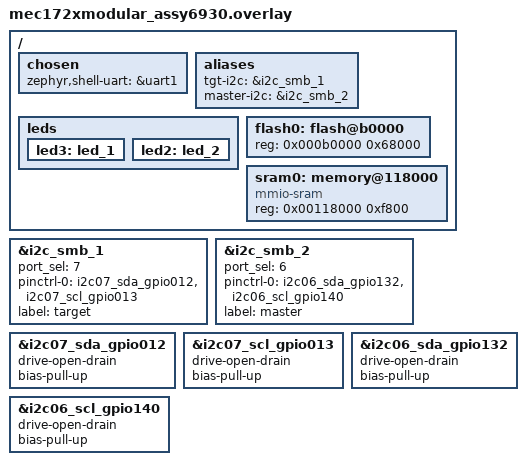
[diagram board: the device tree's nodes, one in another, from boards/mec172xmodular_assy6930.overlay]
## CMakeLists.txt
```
# SPDX-License-Identifier: Apache-2.0

cmake_minimum_required(VERSION 3.20.0)

find_package(Zephyr REQUIRED HINTS $ENV{ZEPHYR_BASE})
project(i2c_shell)

target_sources(app PRIVATE src/main.c)
target_sources(app PRIVATE src/i2c_target.c)
```

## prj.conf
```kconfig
# Driver
CONFIG_I2C=y
CONFIG_I2C_TARGET=y

# console
CONFIG_CONSOLE=y
CONFIG_UART_CONSOLE=y
CONFIG_LOG=y

#SHELL
CONFIG_SHELL=y
CONFIG_GPIO_SHELL=y
CONFIG_I2C_SHELL=y
CONFIG_SHELL_PROMPT_UART="MCHP:~$ "
```

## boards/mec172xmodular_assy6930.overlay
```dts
/*
 * Copyright (c) 2020 Intel Corporation
 *
 * SPDX-License-Identifier: Apache-2.0
 */


/ {
	chosen {
		zephyr,shell-uart = &uart1;
	};

	aliases {
        tgt-i2c = &i2c_smb_1;
        master-i2c = &i2c_smb_2;
    };

	leds {
		led3: led_1 {
			status = "okay";
		};
		led2: led_2 {
			status = "okay";
		};
	};

	/delete-node/ flash@c0000;
	/delete-node/ memory@118000;
	flash0: flash@b0000 {
		reg = <0x000b0000 0x68000>;
	};

	sram0: memory@118000 {
		compatible = "mmio-sram";
		reg = <0x00118000 0xf800>;
	};
};

// Target
&i2c_smb_1 {
    status = "okay";
    port_sel = <7>;
    pinctrl-0 = < &i2c07_sda_gpio012 &i2c07_scl_gpio013 >;  // TP257
	pinctrl-names = "default";

	// port_sel = <1>;
    // pinctrl-0 = < &i2c01_sda_gpio130 &i2c01_scl_gpio131 >;  // TP253
	// pinctrl-names = "default";

    label = "target";
};

// Master
&i2c_smb_2 {
    status = "okay";
    port_sel = <6>;
    pinctrl-0 = < &i2c06_sda_gpio132 &i2c06_scl_gpio140 >; // TP252
	pinctrl-names = "default";

    label = "master";
};

// &i2c01_sda_gpio130{
// 	drive-open-drain;
// 	bias-pull-up;
// };

// &i2c01_scl_gpio131{
// 	drive-open-drain;
// 	bias-pull-up;
// };

&i2c07_sda_gpio012{
	drive-open-drain;
	bias-pull-up;
};

&i2c07_scl_gpio013{
	drive-open-drain;
	bias-pull-up;
};

&i2c06_sda_gpio132{
	drive-open-drain;
	bias-pull-up;
};

&i2c06_scl_gpio140{
	drive-open-drain;
	bias-pull-up;
};
```

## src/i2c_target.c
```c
/*
 * @Author: andy.chang 
 * @Date: 2026-04-16 15:22:05 
 * @Last Modified by: andy.chang
 * @Last Modified time: 2026-04-23 14:50:15
 */

#include <zephyr/drivers/i2c.h>
#include <zephyr/kernel.h>
#include <zephyr/sys/printk.h>
#include <zephyr/logging/log.h>

LOG_MODULE_REGISTER(i2c_tgt, LOG_LEVEL_DBG);

static const struct device *bus = DEVICE_DT_GET(DT_ALIAS(tgt_i2c));

enum {
	I2C_STATE_IDLE = 0,
	I2C_STATE_START_WRITE,
	I2C_STATE_WRITE,
	I2C_STATE_READ,
};

static uint8_t i2c_state = I2C_STATE_IDLE;

static uint8_t idx = 0;
static uint8_t resp_buf[128] = {0};

/*
 * @brief Callback which is called when a write request is received from the
 * master.
 * @param config Pointer to the target configuration.
 */
static int acpi_target_write_requested_cb(struct i2c_target_config *config) {
    LOG_DBG("acpi target write requested");

    i2c_state = I2C_STATE_START_WRITE;
    idx = 0;

    return 0;
}

/*
 * @brief Callback which is called when a write is received from the master.
 * @param config Pointer to the target configuration.
 * @param val The byte received from the master.
 */
static int acpi_target_write_received_cb(struct i2c_target_config *config,
                                        uint8_t val) {
    LOG_DBG("acpi target write received: 0x%02x", val);

    resp_buf[idx++] = val;

    i2c_state = I2C_STATE_WRITE;
    return 0;
}

static int acpi_target_read_processed_cb(struct i2c_target_config *config, uint8_t *val);

static int acpi_target_read_requested_cb(struct i2c_target_config *config, uint8_t *val) {
    i2c_state = I2C_STATE_READ;
    idx = 0;

    return acpi_target_read_processed_cb(config, val);
}

/*
 * @brief Callback which is called when a read request is received from the
 * master.
 * @param config Pointer to the target configuration.
 * @param val Pointer to the byte to be sent to the master.
 */
static int acpi_target_read_processed_cb(struct i2c_target_config *config, uint8_t *val) {
    switch (i2c_state) {
    case I2C_STATE_READ:
        *val = resp_buf[idx++];
        LOG_DBG("acpi target read processed: 0x%02x", *val);
        break;

    default:
        break;
    }

    return 0;
}

/*
 * @brief Callback which is called when the master sends a stop condition.
 * @param config Pointer to the target configuration.
 */
static int acpi_target_stop_cb(struct i2c_target_config *config) {
    LOG_DBG("acpi target stop callback");

    if (i2c_state == I2C_STATE_WRITE) {
        // Send i2c data to ACPI if needed
        LOG_DBG("write data:");

        for (uint8_t i = 0; i < idx; i++) {
            LOG_DBG("\t0x%02x ", resp_buf[i]);
        }
    }

    idx = 0;
    i2c_state = I2C_STATE_IDLE;

    return 0;
}

static struct i2c_target_callbacks acpi_target_callbacks = {
    .write_requested = acpi_target_write_requested_cb,
    .write_received = acpi_target_write_received_cb,
    .read_requested = acpi_target_read_requested_cb,
    .read_processed = acpi_target_read_processed_cb,
    .stop = acpi_target_stop_cb,
};

#define ACPI_ADDR  (0x76)

static struct i2c_target_config target_cfg = {
    .address = ACPI_ADDR,
    .callbacks = &acpi_target_callbacks,
};

#include <zephyr/init.h>

static int init_config(void) {
    int ret;

    ret = i2c_target_register(bus, &target_cfg);

    if (ret < 0) {
        LOG_ERR("Failed to register target: %d", ret);
        return -1;
    }

    for (uint8_t i = 0; i < sizeof(resp_buf); i++) {
        resp_buf[i] = i;
    }

    LOG_INF("Target registered successfully: %d", ret);

    return 0;
}

SYS_INIT(init_config, APPLICATION, 0);
```
